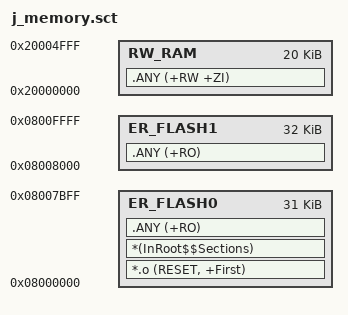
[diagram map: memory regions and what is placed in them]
; STM32F103C8: 64KiB Flash, 20KiB RAM.
; Preserve the ORIGINAL IMU calibration page [0x08007C00,0x08008000).
LR_FLASH0 0x08000000 0x00007C00 {
  ER_FLASH0 0x08000000 0x00007C00 {
    *.o (RESET, +First)
    *(InRoot$$Sections)
    .ANY (+RO)
  }
  RW_RAM 0x20000000 0x00005000 {
    .ANY (+RW +ZI)
  }
}
LR_FLASH1 0x08008000 0x00008000 {
  ER_FLASH1 0x08008000 0x00008000 {
    .ANY (+RO)
  }
}
